# YTM32B1HA0 register map
Vendor: YTMicro; File version: 1.0
CPU: little endian, MPU, FPU, 2 interrupt priority bits
Registers are 32-bit, read-write, reset 0x0 unless marked. A register's access mark holds for its fields unless they carry their own. Offsets are from the block's base; [hi:lo] are bit positions.

## PCU — Power control unit
Base 0x401F8000; register names take the prefix PCU_
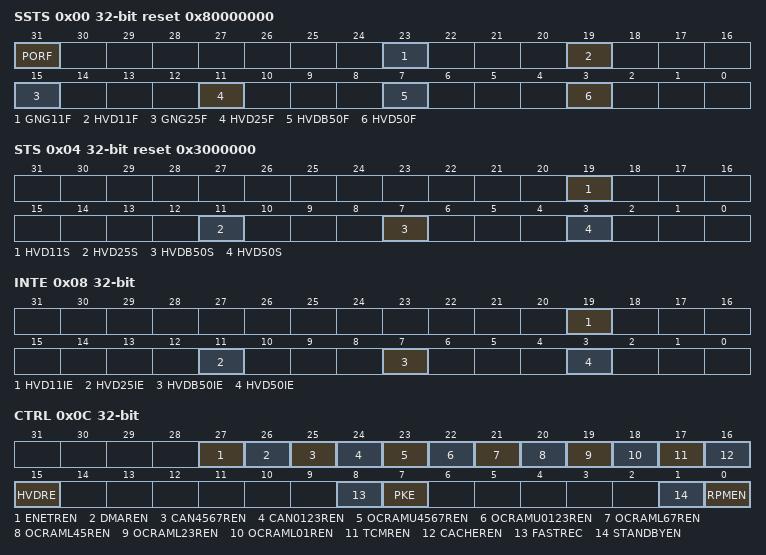
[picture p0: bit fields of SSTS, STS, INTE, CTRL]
0x00 SSTS reset 0x80000000
  [31] PORF — Flags that a power on reset event has occurred. Write 1 to clear it. Other reset sources have no effect.
    0=No power-on reset event has occurred; 1=Power-on reset event has occurred
  [23] GNG11F — Flags that the Go/NoGo sensor has detected a low voltage on the V11 domain in FPM. This applies to only to the part of the domain that supplies the 1.1V clocking modules (e.g. FIRC, SIRC). Write 1 to clear it. Other reset sources have no effect.
    0=No event has occurred; 1=NoGo event has occurred
  [19] HVD11F — This ready-only status bit indicates a high voltage detect event on VDD11. Write 1 to clear this bit.
    0=High voltage event on VDD11 not detected; 1=High voltage event on VDD11 detected
  [15] GNG25F — Flags that the Go/NoGo sensor has detected a low voltage on the V25 domain in FPM. This applies to only to the part of the domain that supplies the 2.5V clocking modules (e.g. FXOSC, PLL). Write 1 to clear it. Other reset sources have no effect.
    0=No event has occurred; 1=NoGo event has occurred
  [11] HVD25F — This ready-only status bit indicates a high voltage detect event on VDD25. Write 1 to clear this bit.
    0=High voltage event on VDD25 not detected; 1=High voltage event on VDD25 detected
  [7] HVDB50F — This ready-only status bit indicates a high voltage detect event on VDD_HVB. Write 1 to clear this bit.
    0=High voltage event on VDD_HVB not detected; 1=High voltage event on VDD_HVB detected
  [3] HVD50F — This ready-only status bit indicates a high voltage detect event on VDD_HVA. Write 1 to clear this bit.
    0=High voltage event on VDD_HVA not detected; 1=High voltage event on VDD_HVA detected
0x04 STS reset 0x3000000
  [19] HVD11S ro — Shows the status of the high voltage detect on VDD11 power domain.
    0=Voltage on VDD11 is below high-voltage detect threshold; 1=Voltage on VDD11 is above high-voltage detect threshold
  [11] HVD25S ro — Shows the status of the high voltage detect on VDD25 power domain.
    0=Voltage on VDD25 is below high-voltage detect threshold; 1=Voltage on VDD25 is above high-voltage detect threshold
  [7] HVDB50S ro — Shows the status of the high voltage detect on VDD_HVB power domain.
    0=Voltage on VDD_HVB is below high-voltage detect threshold; 1=Voltage on VDD_HVB is above high-voltage detect threshold
  [3] HVD50S ro — Shows the status of the high voltage detect on VDD_HVA power domain.
    0=Voltage on VDD_HVA is below high-voltage detect threshold; 1=Voltage on VDD_HVA is above high-voltage detect threshold
0x08 INTE
  [19] HVD11IE — This bit enables hardware interrupt requests if HVD11F is set.
    0=HVD hardware interrupt is disabled (use polling); 1=Request a HVD hardware interrupt when HVD11F is set
  [11] HVD25IE — This bit enables hardware interrupt requests if HVD25F is set.
    0=HVD hardware interrupt is disabled (use polling); 1=Request a HVD hardware interrupt when HVD25F is set
  [7] HVDB50IE — This bit enables hardware interrupt requests if HVDB50F is set.
    0=HVD hardware interrupt is disabled (use polling); 1=Request a HVD hardware interrupt when HVDB50F is set
  [3] HVD50IE — This bit enables hardware interrupt requests if HVD50F is set.
    0=HVD hardware interrupt is disabled (use polling); 1=Request a HVD hardware interrupt when HVD50F is set
0x0C CTRL
  [27] ENETREN — This bit controls whether Ethernet RAM enters retention state when chip enters standby mode.
    0=Ethernet RAM doesn't enter retention state when chip enters standby mode; 1=Ethernet RAM enters retention state when chip enters standby mode
  [26] DMAREN — This bit controls whether DMA RAM enters retention state when chip enters standby mode.
    0=DMA RAM doesn't enter retention state when chip enters standby mode; 1=DMA RAM enters retention state when chip enters standby mode
  [25] CAN4567REN — This bit controls whether CAN4/5/6/7 RAM enters retention state when chip enters standby mode.
    0=CAN4/5/6/7 RAM doesn't enter retention state when chip enters standby mode; 1=CAN4/5/6/7 RAM enters retention state when chip enters standby mode
  [24] CAN0123REN — This bit controls whether CAN0/1/2/3 RAM enters retention state when chip enters standby mode.
    0=CAN0/1/2/3 RAM doesn't enter retention state when chip enters standby mode; 1=CAN0/1/2/3 RAM enters retention state when chip enters standby mode
  [23] OCRAMU4567REN — This bit controls whether OCRAMU Block4/5/6/7 enters retention state when chip enters standby mode.
    0=OCRAMU Block4/5/6/7 doesn't enter retention state when chip enters standby mode; 1=OCRAMU Block4/5/6/7 enters retention state when chip enters standby mode
  [22] OCRAMU0123REN — This bit controls whether OCRAMU Block0/1/2/3 enters retention state when chip enters standby mode.
    0=OCRAMU Block0/1/2/3 doesn't enter retention state when chip enters standby mode; 1=OCRAMU Block0/1/2/3 enters retention state when chip enters standby mode
  [21] OCRAML67REN — This bit controls whether OCRAML Block6/7 enters retention state when chip enters standby mode.
    0=OCRAML Block6/7 doesn't enter retention state when chip enters standby mode; 1=OCRAML Block6/7 enters retention state when chip enters standby mode
  [20] OCRAML45REN — This bit controls whether OCRAML Block4/5 enters retention state when chip enters standby mode.
    0=OCRAML Block4/5 doesn't enter retention state when chip enters standby mode; 1=OCRAML Block4/5 enters retention state when chip enters standby mode
  [19] OCRAML23REN — This bit controls whether OCRAML Block2/3 enters retention state when chip enters standby mode.
    0=OCRAML Block2/3 doesn't enter retention state when chip enters standby mode; 1=OCRAML Block2/3 enters retention state when chip enters standby mode
  [18] OCRAML01REN — This bit controls whether OCRAML Block0/1 enters retention state when chip enters standby mode.
    0=OCRAML Block0/1 doesn't enter retention state when chip enters standby mode; 1=OCRAML Block0/1 enters retention state when chip enters standby mode
  [17] TCMREN — This bit controls whether ITCM/DTCM enters retention state when chip enters standby mode.
    0=ITCM/DTCM doesn't enter retention state when chip enters standby mode; 1=ITCM/DTCM enters retention state when chip enters standby mode
  [16] CACHEREN — This bit controls whether Cache RAM enters retention state when chip enters standby mode.
    0=Cache RAM doesn't enter retention state when chip enters standby mode; 1=Cache RAM enters retention state when chip enters standby mode
  [15] HVDRE — This bit controls whether high voltage detect event generates a reset.
    0=Don't generate reset when a high voltage detect event occurs; 1=Generate reset when a high voltage detect event occurs
  [8] FASTREC — This bit controls the recovery time from Low Power Mode (LPM) to Full Performance Mode (FPM). At recovery from Low Power Mode all the tank capacitors from the secondary supplies have to re recharged. This causes a high current demand, that might not be met by the supply driving the VDD_HVA primary domain. When selecting the fast recovery time, the current for recharging is approximately 3 times higher than for FASTREC=0.
    0=Normal recovery time from LPM; 1=Fast recovery time from LPM
  [7] PKE — This bit is to control PAD state when wakeup from power mode.
    0=PAD state is reseted when wakeup from Powerdown mode; 1=PAD state is kept when wakeup from Powerdown mode until PKE bit is cleared to 0
  [1] STANDBYEN — This bit enables chip to enter Standby mode.
    0=Disable Standby mode entry; 1=Enable Standby mode entry
  [0] RPMEN — This bit controls the reduce performance mode entry or not.
    0=Disable RPM entry; 1=Enable RPM entry
